# STM32L4S7 register map
File version: 2.2
CPU: CM4 r0p1, little endian, MPU, FPU, 4 interrupt priority bits
Registers are 32-bit, read-write, reset 0x0 unless marked. A register's access mark holds for its fields unless they carry their own. Offsets are from the block's base; [hi:lo] are bit positions; {n}, {i} and the like mark numbered series.

## SYSCFG — System configuration controller
Base 0x40010000
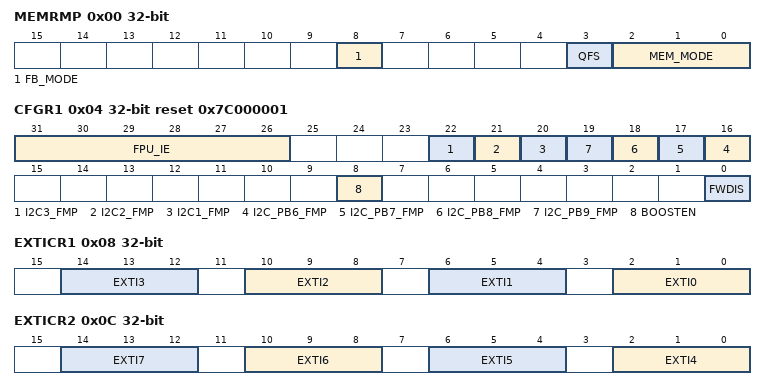
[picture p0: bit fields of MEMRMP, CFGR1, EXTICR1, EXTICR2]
0x00 MEMRMP — memory remap register
  [8] FB_MODE — Flash Bank mode selection
  [3] QFS — QUADSPI memory mapping swap
  [2:0] MEM_MODE — Memory mapping selection
0x04 CFGR1 reset 0x7C000001 — configuration register 1
  [31:26] FPU_IE — Floating Point Unit interrupts enable bits
  [22] I2C3_FMP — I2C3 Fast-mode Plus driving capability activation
  [21] I2C2_FMP — I2C2 Fast-mode Plus driving capability activation
  [20] I2C1_FMP — I2C1 Fast-mode Plus driving capability activation
  [n+10] I2C_PB{n}_FMP (n=6..9) — Fast-mode Plus (Fm+) driving capability activation on PB{n}
  [8] BOOSTEN — I/O analog switch voltage booster enable
  [0] FWDIS — Firewall disable
0x08 EXTICR1 — external interrupt configuration register 1
  [4n+2:4n] EXTI{n} (n=0..3) — EXTI {n} configuration bits
0x0C EXTICR2 — external interrupt configuration register 2
  [4n-14:4n-16] EXTI{n} (n=4..7) — EXTI {n} configuration bits
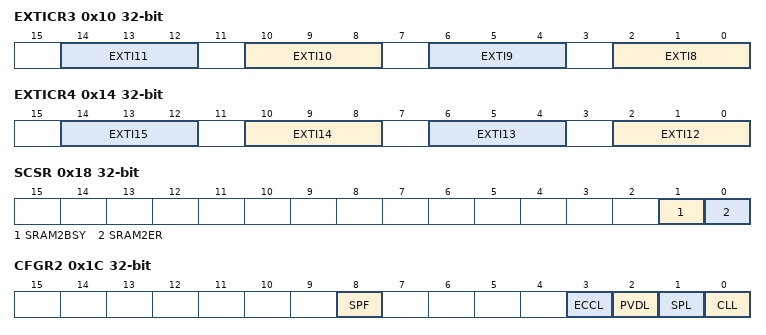
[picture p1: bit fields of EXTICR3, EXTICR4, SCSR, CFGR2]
0x10 EXTICR3 — external interrupt configuration register 3
  [4n-30:4n-32] EXTI{n} (n=8..11) — EXTI {n} configuration bits
0x14 EXTICR4 — external interrupt configuration register 4
  [4n-46:4n-48] EXTI{n} (n=12..15) — EXTI{n} configuration bits
0x18 SCSR access per field
  [1] SRAM2BSY ro — SRAM2 busy by erase operation
  [0] SRAM2ER rw — SRAM2 Erase
0x1C CFGR2 access per field
  [8] SPF rw — SRAM2 parity error flag
  [3] ECCL wo — ECC Lock
  [2] PVDL wo — PVD lock enable bit
  [1] SPL wo — SRAM2 parity lock bit
  [0] CLL wo — Cortex-M4 LOCKUP (Hardfault) output enable bit
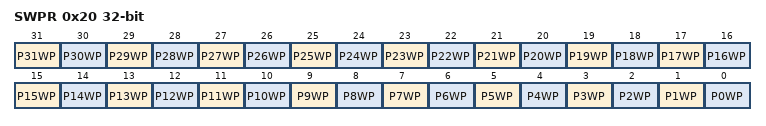
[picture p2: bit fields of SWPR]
0x20 SWPR wo
  [31] P31WP — SRAM2 page 31 write protection
  [n] P{n}WP (n=0..30)
0x24 SKR wo
  [7:0] KEY — SRAM2 write protection key for software erase

## RNG — Random number generator
Base 0x50060800
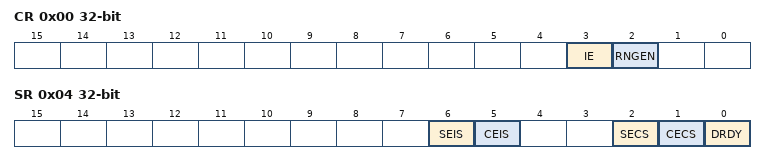
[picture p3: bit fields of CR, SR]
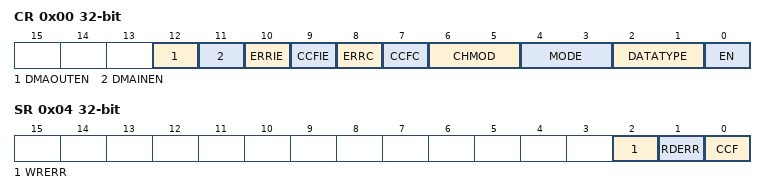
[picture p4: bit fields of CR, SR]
0x00 CR — control register
  [3] IE — Interrupt enable
  [2] RNGEN — Random number generator enable
0x04 SR access per field — status register
  [6] SEIS rw — Seed error interrupt status
  [5] CEIS rw — Clock error interrupt status
  [2] SECS ro — Seed error current status
  [1] CECS ro — Clock error current status
  [0] DRDY ro — Data ready
0x08 DR ro — data register
  [31:0] RNDATA — Random data

## AES — Advanced encryption standard hardware accelerator
Base 0x50060000
0x00 CR — control register
  [12] DMAOUTEN — Enable DMA management of data output phase
  [11] DMAINEN — Enable DMA management of data input phase
  [10] ERRIE — Error interrupt enable
  [9] CCFIE — CCF flag interrupt enable
  [8] ERRC — Error clear
  [7] CCFC — Computation Complete Flag Clear
  [6:5] CHMOD — AES chaining mode
  [4:3] MODE — AES operating mode
  [2:1] DATATYPE — Data type selection (for data in and data out to/from the cryptographic block)
  [0] EN — AES enable
0x04 SR ro — status register
  [2] WRERR — Write error flag
  [1] RDERR — Read error flag
  [0] CCF — Computation complete flag
0x08 DINR — data input register
  [31:0] AES_DINR — Data Input Register
0x0C DOUTR ro — data output register
  [31:0] AES_DOUTR — Data output register
0x10 KEYR0 — key register 0
  [31:0] AES_KEYR0 — Data Output Register (LSB key [31:0])
0x14 KEYR1 — key register 1
  [31:0] AES_KEYR1 — AES key register (key [63:32])
0x18 KEYR2 — key register 2
  [31:0] AES_KEYR2 — AES key register (key [95:64])
0x1C KEYR3 — key register 3
  [31:0] AES_KEYR3 — AES key register (MSB key [127:96])
0x20 IVR0 — initialization vector register 0
  [31:0] AES_IVR0 — initialization vector register (LSB IVR [31:0])
0x24 IVR1 — initialization vector register 1
  [31:0] AES_IVR1 — Initialization Vector Register (IVR [63:32])
0x28 IVR2 — initialization vector register 2
  [31:0] AES_IVR2 — Initialization Vector Register (IVR [95:64])
0x2C IVR3 — initialization vector register 3
  [31:0] AES_IVR3 — Initialization Vector Register (MSB IVR [127:96])
